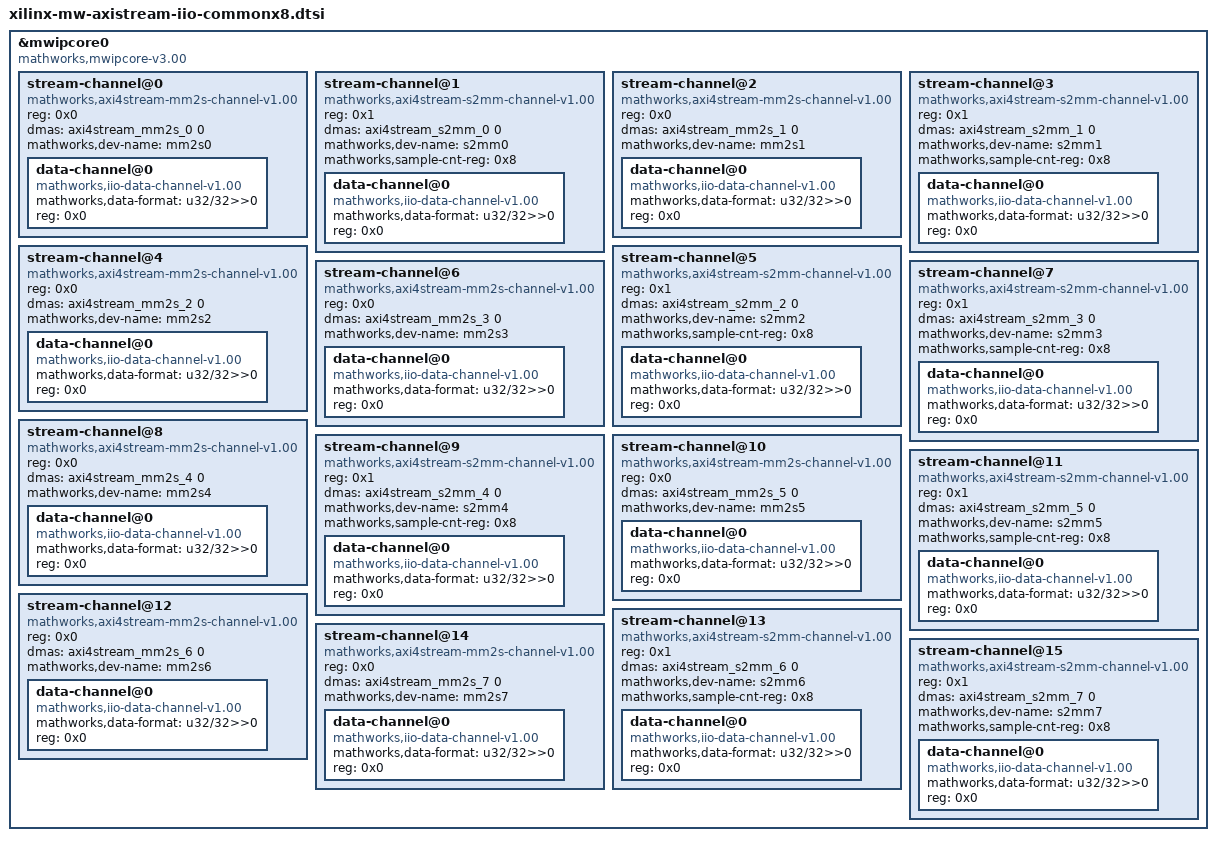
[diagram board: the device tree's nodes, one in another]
#include "xilinx-mw-axistream-dmax8.dtsi"

&mwipcore0 {
	compatible = "mathworks,mwipcore-v3.00";
	#address-cells = <1>;
	#size-cells = <0>;
	stream-channel@0 {			
		#address-cells = <1>;
		#size-cells = <0>;
		reg = <0x0>;
		compatible = "mathworks,axi4stream-mm2s-channel-v1.00";
		dma-names = "mm2s";
		dmas = <&axi4stream_mm2s_0 0>;
		mathworks,dev-name = "mm2s0";

		data-channel@0 {
			compatible = "mathworks,iio-data-channel-v1.00";
			mathworks,data-format = "u32/32>>0";
			reg = <0x0>;
		};
	};
	stream-channel@1 {
		reg = <0x1>;
		#address-cells = <1>;
		#size-cells = <0>;
		compatible = "mathworks,axi4stream-s2mm-channel-v1.00";
		dma-names = "s2mm";
		dmas = <&axi4stream_s2mm_0 0>;
		mathworks,dev-name = "s2mm0";
		mathworks,sample-cnt-reg = <0x8>;

		data-channel@0 {
			compatible = "mathworks,iio-data-channel-v1.00";
			mathworks,data-format = "u32/32>>0";
			reg = <0x0>;
		};
	};
	stream-channel@2 {			
		#address-cells = <1>;
		#size-cells = <0>;
		reg = <0x0>;
		compatible = "mathworks,axi4stream-mm2s-channel-v1.00";
		dma-names = "mm2s";
		dmas = <&axi4stream_mm2s_1 0>;
		mathworks,dev-name = "mm2s1";

		data-channel@0 {
			compatible = "mathworks,iio-data-channel-v1.00";
			mathworks,data-format = "u32/32>>0";
			reg = <0x0>;
		};
	};
	stream-channel@3 {
		reg = <0x1>;
		#address-cells = <1>;
		#size-cells = <0>;
		compatible = "mathworks,axi4stream-s2mm-channel-v1.00";
		dma-names = "s2mm";
		dmas = <&axi4stream_s2mm_1 0>;
		mathworks,dev-name = "s2mm1";
		mathworks,sample-cnt-reg = <0x8>;

		data-channel@0 {
			compatible = "mathworks,iio-data-channel-v1.00";
			mathworks,data-format = "u32/32>>0";
			reg = <0x0>;
		};
	};
	stream-channel@4 {			
		#address-cells = <1>;
		#size-cells = <0>;
		reg = <0x0>;
		compatible = "mathworks,axi4stream-mm2s-channel-v1.00";
		dma-names = "mm2s";
		dmas = <&axi4stream_mm2s_2 0>;
		mathworks,dev-name = "mm2s2";

		data-channel@0 {
			compatible = "mathworks,iio-data-channel-v1.00";
			mathworks,data-format = "u32/32>>0";
			reg = <0x0>;
		};
	};
	stream-channel@5 {
		reg = <0x1>;
		#address-cells = <1>;
		#size-cells = <0>;
		compatible = "mathworks,axi4stream-s2mm-channel-v1.00";
		dma-names = "s2mm";
		dmas = <&axi4stream_s2mm_2 0>;
		mathworks,dev-name = "s2mm2";
		mathworks,sample-cnt-reg = <0x8>;

		data-channel@0 {
			compatible = "mathworks,iio-data-channel-v1.00";
			mathworks,data-format = "u32/32>>0";
			reg = <0x0>;
		};
	};
	stream-channel@6 {			
		#address-cells = <1>;
		#size-cells = <0>;
		reg = <0x0>;
		compatible = "mathworks,axi4stream-mm2s-channel-v1.00";
		dma-names = "mm2s";
		dmas = <&axi4stream_mm2s_3 0>;
		mathworks,dev-name = "mm2s3";

		data-channel@0 {
			compatible = "mathworks,iio-data-channel-v1.00";
			mathworks,data-format = "u32/32>>0";
			reg = <0x0>;
		};
	};
	stream-channel@7 {
		reg = <0x1>;
		#address-cells = <1>;
		#size-cells = <0>;
		compatible = "mathworks,axi4stream-s2mm-channel-v1.00";
		dma-names = "s2mm";
		dmas = <&axi4stream_s2mm_3 0>;
		mathworks,dev-name = "s2mm3";
		mathworks,sample-cnt-reg = <0x8>;

		data-channel@0 {
			compatible = "mathworks,iio-data-channel-v1.00";
			mathworks,data-format = "u32/32>>0";
			reg = <0x0>;
		};
	};
	stream-channel@8 {			
		#address-cells = <1>;
		#size-cells = <0>;
		reg = <0x0>;
		compatible = "mathworks,axi4stream-mm2s-channel-v1.00";
		dma-names = "mm2s";
		dmas = <&axi4stream_mm2s_4 0>;
		mathworks,dev-name = "mm2s4";

		data-channel@0 {
			compatible = "mathworks,iio-data-channel-v1.00";
			mathworks,data-format = "u32/32>>0";
			reg = <0x0>;
		};
	};
	stream-channel@9 {
		reg = <0x1>;
		#address-cells = <1>;
		#size-cells = <0>;
		compatible = "mathworks,axi4stream-s2mm-channel-v1.00";
		dma-names = "s2mm";
		dmas = <&axi4stream_s2mm_4 0>;
		mathworks,dev-name = "s2mm4";
		mathworks,sample-cnt-reg = <0x8>;

		data-channel@0 {
			compatible = "mathworks,iio-data-channel-v1.00";
			mathworks,data-format = "u32/32>>0";
			reg = <0x0>;
		};
	};
	stream-channel@10 {			
		#address-cells = <1>;
		#size-cells = <0>;
		reg = <0x0>;
		compatible = "mathworks,axi4stream-mm2s-channel-v1.00";
		dma-names = "mm2s";
		dmas = <&axi4stream_mm2s_5 0>;
		mathworks,dev-name = "mm2s5";

		data-channel@0 {
			compatible = "mathworks,iio-data-channel-v1.00";
			mathworks,data-format = "u32/32>>0";
			reg = <0x0>;
		};
	};
	stream-channel@11 {
		reg = <0x1>;
		#address-cells = <1>;
		#size-cells = <0>;
		compatible = "mathworks,axi4stream-s2mm-channel-v1.00";
		dma-names = "s2mm";
		dmas = <&axi4stream_s2mm_5 0>;
		mathworks,dev-name = "s2mm5";
		mathworks,sample-cnt-reg = <0x8>;

		data-channel@0 {
			compatible = "mathworks,iio-data-channel-v1.00";
			mathworks,data-format = "u32/32>>0";
			reg = <0x0>;
		};
	};
	stream-channel@12 {			
		#address-cells = <1>;
		#size-cells = <0>;
		reg = <0x0>;
		compatible = "mathworks,axi4stream-mm2s-channel-v1.00";
		dma-names = "mm2s";
		dmas = <&axi4stream_mm2s_6 0>;
		mathworks,dev-name = "mm2s6";

		data-channel@0 {
			compatible = "mathworks,iio-data-channel-v1.00";
			mathworks,data-format = "u32/32>>0";
			reg = <0x0>;
		};
	};
	stream-channel@13 {
		reg = <0x1>;
		#address-cells = <1>;
		#size-cells = <0>;
		compatible = "mathworks,axi4stream-s2mm-channel-v1.00";
		dma-names = "s2mm";
		dmas = <&axi4stream_s2mm_6 0>;
		mathworks,dev-name = "s2mm6";
		mathworks,sample-cnt-reg = <0x8>;

		data-channel@0 {
			compatible = "mathworks,iio-data-channel-v1.00";
			mathworks,data-format = "u32/32>>0";
			reg = <0x0>;
		};
	};
	stream-channel@14 {			
		#address-cells = <1>;
		#size-cells = <0>;
		reg = <0x0>;
		compatible = "mathworks,axi4stream-mm2s-channel-v1.00";
		dma-names = "mm2s";
		dmas = <&axi4stream_mm2s_7 0>;
		mathworks,dev-name = "mm2s7";

		data-channel@0 {
			compatible = "mathworks,iio-data-channel-v1.00";
			mathworks,data-format = "u32/32>>0";
			reg = <0x0>;
		};
	};
	stream-channel@15 {
		reg = <0x1>;
		#address-cells = <1>;
		#size-cells = <0>;
		compatible = "mathworks,axi4stream-s2mm-channel-v1.00";
		dma-names = "s2mm";
		dmas = <&axi4stream_s2mm_7 0>;
		mathworks,dev-name = "s2mm7";
		mathworks,sample-cnt-reg = <0x8>;

		data-channel@0 {
			compatible = "mathworks,iio-data-channel-v1.00";
			mathworks,data-format = "u32/32>>0";
			reg = <0x0>;
		};
	};
};

